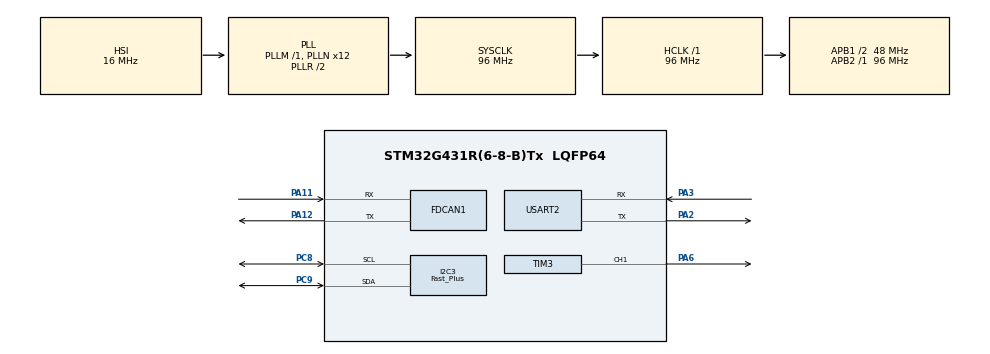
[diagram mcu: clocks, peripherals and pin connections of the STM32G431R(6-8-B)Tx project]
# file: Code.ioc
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Dma.Request0=TIM3_CH1
Dma.TIM3_CH1.0.Direction=DMA_MEMORY_TO_PERIPH
Dma.TIM3_CH1.0.EventEnable=DISABLE
Dma.TIM3_CH1.0.Instance=DMA1_Channel1
Dma.TIM3_CH1.0.MemDataAlignment=DMA_MDATAALIGN_HALFWORD
Dma.TIM3_CH1.0.MemInc=DMA_MINC_ENABLE
Dma.TIM3_CH1.0.Mode=DMA_NORMAL
Dma.TIM3_CH1.0.PeriphDataAlignment=DMA_PDATAALIGN_HALFWORD
Dma.TIM3_CH1.0.PeriphInc=DMA_PINC_DISABLE
Dma.TIM3_CH1.0.Polarity=HAL_DMAMUX_REQ_GEN_RISING
Dma.TIM3_CH1.0.Priority=DMA_PRIORITY_LOW
Dma.TIM3_CH1.0.RequestNumber=1
Dma.TIM3_CH1.0.SignalID=NONE
Dma.TIM3_CH1.0.SyncEnable=DISABLE
Dma.TIM3_CH1.0.SyncPolarity=HAL_DMAMUX_SYNC_NO_EVENT
Dma.TIM3_CH1.0.SyncRequestNumber=1
Dma.TIM3_CH1.0.SyncSignalID=NONE
FDCAN1.CalculateBaudRateNominal=500000
FDCAN1.CalculateTimeBitNominal=2000
FDCAN1.CalculateTimeQuantumNominal=125.0
FDCAN1.NominalPrescaler=6
FDCAN1.NominalTimeSeg1=13
FDCAN1.NominalTimeSeg2=2
I2C3.I2C_Speed_Mode=I2C_Fast_Plus
I2C3.Timing=0x00700814
Mcu.Family=STM32G4
Mcu.Name=STM32G431R(6-8-B)Tx
Mcu.Package=LQFP64
NVIC.DMA1_Channel1_IRQn=true\:0\:0\:false\:false\:true\:false\:true\:true
NVIC.PriorityGroup=NVIC_PRIORITYGROUP_4
PA11.Mode=FDCAN_Activate
PA11.Signal=FDCAN1_RX
PA12.Mode=FDCAN_Activate
PA12.Signal=FDCAN1_TX
PA2.Mode=Asynchronous
PA2.Signal=USART2_TX
PA3.Mode=Asynchronous
PA3.Signal=USART2_RX
PA6.Signal=S_TIM3_CH1
PC8.Mode=I2C
PC8.Signal=I2C3_SCL
PC9.Mode=I2C
PC9.Signal=I2C3_SDA
ProjectManager.HeapSize=0x200
ProjectManager.StackSize=0x400
ProjectManager.TargetToolchain=Makefile
RCC.ADC12Freq_Value=96000000
RCC.AHBFreq_Value=96000000
RCC.APB1CLKDivider=RCC_HCLK_DIV2
RCC.APB1Freq_Value=48000000
RCC.APB1TimFreq_Value=96000000
RCC.APB2Freq_Value=96000000
RCC.APB2TimFreq_Value=96000000
RCC.CortexFreq_Value=96000000
RCC.EXTERNAL_CLOCK_VALUE=12288000
RCC.HCLKFreq_Value=96000000
RCC.HSE_VALUE=8000000
RCC.HSI48_VALUE=48000000
RCC.HSI_VALUE=16000000
RCC.LSE_VALUE=32768
RCC.PLLN=12
RCC.SYSCLKFreq_VALUE=96000000
RCC.SYSCLKSource=RCC_SYSCLKSOURCE_PLLCLK
RCC.USBFreq_Value=96000000
RCC.VCOOutputFreq_Value=192000000
SH.S_TIM3_CH1.0=TIM3_CH1,PWM Generation1 CH1
TIM3.Channel-PWM\ Generation1\ CH1=TIM_CHANNEL_1
TIM3.PeriodNoDither=120-1
USART2.VirtualMode-Asynchronous=VM_ASYNC
VP_SYS_VS_DBSignals.Mode=DisableDeadBatterySignals
VP_TIM3_VS_ClockSourceINT.Mode=Internal
board=custom

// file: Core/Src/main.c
/* USER CODE BEGIN Header */
/**
  ******************************************************************************
  * @file           : main.c
  * @brief          : Main program body
  ******************************************************************************
  * @attention
  *
  * Copyright (c) 2024 STMicroelectronics.
  * All rights reserved.
  *
  * This software is licensed under terms that can be found in the LICENSE file
  * in the root directory of this software component.
  * If no LICENSE file comes with this software, it is provided AS-IS.
  *
  ******************************************************************************
  */
/* USER CODE END Header */
#include "main.h"
#include "dma.h"
#include "fdcan.h"
#include "i2c.h"
#include "tim.h"
#include "usart.h"
#include "gpio.h"

/* USER CODE BEGIN Includes */
#include "main_entry.h"

/* USER CODE END Includes */

void SystemClock_Config(void);

int main(void)
{

  /* MCU Configuration--------------------------------------------------------*/

  /* Reset of all peripherals, Initializes the Flash interface and the Systick. */
  HAL_Init();

  /* Configure the system clock */
  SystemClock_Config();

  /* Initialize all configured peripherals */
  MX_GPIO_Init();
  MX_DMA_Init();
  MX_FDCAN1_Init();
  MX_USART2_UART_Init();
  MX_I2C3_Init();
  MX_TIM3_Init();
  /* USER CODE BEGIN 2 */
  main_entry_func();

  /* USER CODE END 2 */

  /* Infinite loop */
  while (1)
  {

  }
}

void SystemClock_Config(void)
{
  RCC_OscInitTypeDef RCC_OscInitStruct = {0};
  RCC_ClkInitTypeDef RCC_ClkInitStruct = {0};

  /** Configure the main internal regulator output voltage
  */
  HAL_PWREx_ControlVoltageScaling(PWR_REGULATOR_VOLTAGE_SCALE1);

  /** Initializes the RCC Oscillators according to the specified parameters
  * in the RCC_OscInitTypeDef structure.
  */
  RCC_OscInitStruct.OscillatorType = RCC_OSCILLATORTYPE_HSI;
  RCC_OscInitStruct.HSIState = RCC_HSI_ON;
  RCC_OscInitStruct.HSICalibrationValue = RCC_HSICALIBRATION_DEFAULT;
  RCC_OscInitStruct.PLL.PLLState = RCC_PLL_ON;
  RCC_OscInitStruct.PLL.PLLSource = RCC_PLLSOURCE_HSI;
  RCC_OscInitStruct.PLL.PLLM = RCC_PLLM_DIV1;
  RCC_OscInitStruct.PLL.PLLN = 12;
  RCC_OscInitStruct.PLL.PLLP = RCC_PLLP_DIV2;
  RCC_OscInitStruct.PLL.PLLQ = RCC_PLLQ_DIV2;
  RCC_OscInitStruct.PLL.PLLR = RCC_PLLR_DIV2;
  if (HAL_RCC_OscConfig(&RCC_OscInitStruct) != HAL_OK)
  {
    Error_Handler();
  }

  /** Initializes the CPU, AHB and APB buses clocks
  */
  RCC_ClkInitStruct.ClockType = RCC_CLOCKTYPE_HCLK|RCC_CLOCKTYPE_SYSCLK
                              |RCC_CLOCKTYPE_PCLK1|RCC_CLOCKTYPE_PCLK2;
  RCC_ClkInitStruct.SYSCLKSource = RCC_SYSCLKSOURCE_PLLCLK;
  RCC_ClkInitStruct.AHBCLKDivider = RCC_SYSCLK_DIV1;
  RCC_ClkInitStruct.APB1CLKDivider = RCC_HCLK_DIV2;
  RCC_ClkInitStruct.APB2CLKDivider = RCC_HCLK_DIV1;

  if (HAL_RCC_ClockConfig(&RCC_ClkInitStruct, FLASH_LATENCY_3) != HAL_OK)
  {
    Error_Handler();
  }
}

void Error_Handler(void)
{
  __disable_irq();
  while (1)
  {
  }
}
